# CTRL_MODULE_CORE register map
Vendor: Texas Instruments
Registers are 32-bit, access per field, reset 0x0 unless marked. A register's access mark holds for its fields unless they carry their own. Offsets are as the file gives them; [hi:lo] are bit positions; {n}, {i} and the like mark numbered series; 'fields as' and 'values as' point back to an identical list.

## CTRL_MODULE_CORE (part 5 of 5)
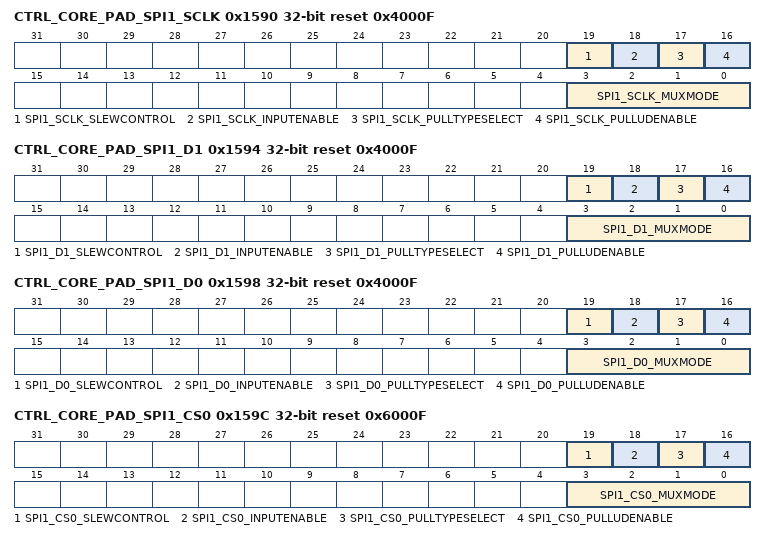
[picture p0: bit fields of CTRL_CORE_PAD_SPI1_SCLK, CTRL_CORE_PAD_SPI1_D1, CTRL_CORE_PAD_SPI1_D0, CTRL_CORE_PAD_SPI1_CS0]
0x1590 CTRL_CORE_PAD_SPI1_SCLK reset 0x4000F
  [19] SPI1_SCLK_SLEWCONTROL rw
    0=Fast_slew_is_selected; 1=Slow_slew_is_selected
  [18] SPI1_SCLK_INPUTENABLE rw
    0=Receive_mode_is_disabled; 1=Receive_mode_is_enabled
  [17] SPI1_SCLK_PULLTYPESELECT rw
    0=Pull_Down_is_selected; 1=Pull_Up_is_selected
  [16] SPI1_SCLK_PULLUDENABLE rw
    0=Enables_weak_Pull_Up/Down; 1=Disables_weak_Pull_Up/Down
  [3:0] SPI1_SCLK_MUXMODE rw
    0=SPI1_SCLK; 1=UART3_RXD; 14=GPIO4_0; 15=DRIVER_OFF
0x1594 CTRL_CORE_PAD_SPI1_D1 reset 0x4000F
  [19] SPI1_D1_SLEWCONTROL rw
    0=Fast_slew_is_selected; 1=Slow_slew_is_selected
  [18] SPI1_D1_INPUTENABLE rw
    0=Receive_mode_is_disabled; 1=Receive_mode_is_enabled
  [17] SPI1_D1_PULLTYPESELECT rw
    0=Pull_Down_is_selected; 1=Pull_Up_is_selected
  [16] SPI1_D1_PULLUDENABLE rw
    0=Enables_weak_Pull_Up/Down; 1=Disables_weak_Pull_Up/Down
  [3:0] SPI1_D1_MUXMODE rw
    0=SPI1_D1; 1=UART3_CTSN; 14=GPIO4_1; 15=DRIVER_OFF
0x1598 CTRL_CORE_PAD_SPI1_D0 reset 0x4000F
  [19] SPI1_D0_SLEWCONTROL rw
    0=Fast_slew_is_selected; 1=Slow_slew_is_selected
  [18] SPI1_D0_INPUTENABLE rw
    0=Receive_mode_is_disabled; 1=Receive_mode_is_enabled
  [17] SPI1_D0_PULLTYPESELECT rw
    0=Pull_Down_is_selected; 1=Pull_Up_is_selected
  [16] SPI1_D0_PULLUDENABLE rw
    0=Enables_weak_Pull_Up/Down; 1=Disables_weak_Pull_Up/Down
  [3:0] SPI1_D0_MUXMODE rw
    0=SPI1_D0; 1=UART3_RTSN; 14=GPIO4_2; 15=DRIVER_OFF
0x159C CTRL_CORE_PAD_SPI1_CS0 reset 0x6000F
  [19] SPI1_CS0_SLEWCONTROL rw
    0=Fast_slew_is_selected; 1=Slow_slew_is_selected
  [18] SPI1_CS0_INPUTENABLE rw
    0=Receive_mode_is_disabled; 1=Receive_mode_is_enabled
  [17] SPI1_CS0_PULLTYPESELECT rw
    0=Pull_Down_is_selected; 1=Pull_Up_is_selected
  [16] SPI1_CS0_PULLUDENABLE rw
    0=Enables_weak_Pull_Up/Down; 1=Disables_weak_Pull_Up/Down
  [3:0] SPI1_CS0_MUXMODE rw
    0=SPI1_CS0; 1=UART3_TXD; 14=GPIO4_3; 15=DRIVER_OFF
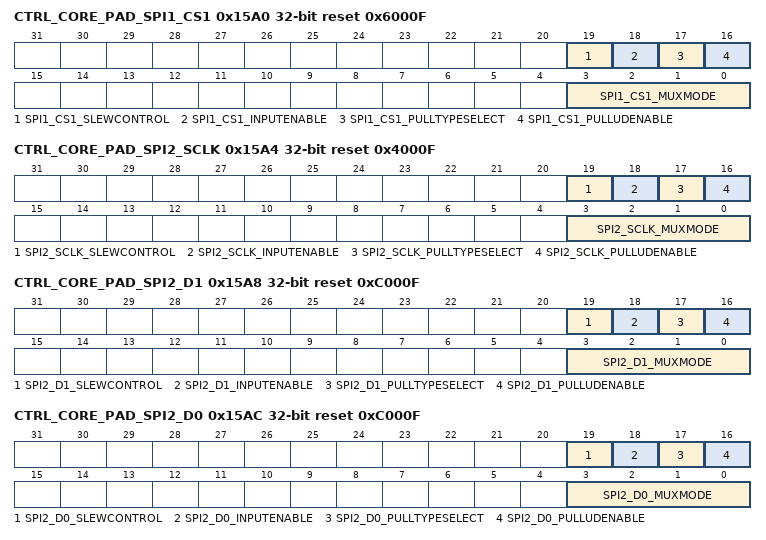
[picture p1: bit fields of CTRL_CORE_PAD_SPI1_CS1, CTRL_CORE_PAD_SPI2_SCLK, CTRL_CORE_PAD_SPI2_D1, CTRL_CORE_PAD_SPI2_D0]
0x15A0 CTRL_CORE_PAD_SPI1_CS1 reset 0x6000F
  [19] SPI1_CS1_SLEWCONTROL rw
    0=Fast_slew_is_selected; 1=Slow_slew_is_selected
  [18] SPI1_CS1_INPUTENABLE rw
    0=Receive_mode_is_disabled; 1=Receive_mode_is_enabled
  [17] SPI1_CS1_PULLTYPESELECT rw
    0=Pull_Down_is_selected; 1=Pull_Up_is_selected
  [16] SPI1_CS1_PULLUDENABLE rw
    0=Enables_weak_Pull_Up/Down; 1=Disables_weak_Pull_Up/Down
  [3:0] SPI1_CS1_MUXMODE rw
    0=SPI1_CS1; 1=SPI3_CS1; 4=TIMER6; 7=EHRPWM1_TRIPZONE_INPUT; 14=GPIO4_4; 15=DRIVER_OFF
0x15A4 CTRL_CORE_PAD_SPI2_SCLK reset 0x4000F
  [19] SPI2_SCLK_SLEWCONTROL rw
    0=Fast_slew_is_selected; 1=Slow_slew_is_selected
  [18] SPI2_SCLK_INPUTENABLE rw
    0=Receive_mode_is_disabled; 1=Receive_mode_is_enabled
  [17] SPI2_SCLK_PULLTYPESELECT rw
    0=Pull_Down_is_selected; 1=Pull_Up_is_selected
  [16] SPI2_SCLK_PULLUDENABLE rw
    0=Enables_weak_Pull_Up/Down; 1=Disables_weak_Pull_Up/Down
  [3:0] SPI2_SCLK_MUXMODE rw
    0=SPI2_SCLK; 1=UART3_RXD; 2=EHRPWM1A; 3=TIMER3; 14=GPIO4_5; 15=DRIVER_OFF
0x15A8 CTRL_CORE_PAD_SPI2_D1 reset 0xC000F
  [19] SPI2_D1_SLEWCONTROL rw
    0=Fast_slew_is_selected; 1=Slow_slew_is_selected
  [18] SPI2_D1_INPUTENABLE rw
    0=Receive_mode_is_disabled; 1=Receive_mode_is_enabled
  [17] SPI2_D1_PULLTYPESELECT rw
    0=Pull_Down_is_selected; 1=Pull_Up_is_selected
  [16] SPI2_D1_PULLUDENABLE rw
    0=Enables_weak_Pull_Up/Down; 1=Disables_weak_Pull_Up/Down
  [3:0] SPI2_D1_MUXMODE rw
    0=SPI2_D1; 1=UART3_CTSN; 3=TIMER5; 7=ECAP1_IN_PWM1_OUT; 14=GPIO4_6; 15=DRIVER_OFF
0x15AC CTRL_CORE_PAD_SPI2_D0 reset 0xC000F
  [19] SPI2_D0_SLEWCONTROL rw
    0=Fast_slew_is_selected; 1=Slow_slew_is_selected
  [18] SPI2_D0_INPUTENABLE rw
    0=Receive_mode_is_disabled; 1=Receive_mode_is_enabled
  [17] SPI2_D0_PULLTYPESELECT rw
    0=Pull_Down_is_selected; 1=Pull_Up_is_selected
  [16] SPI2_D0_PULLUDENABLE rw
    0=Enables_weak_Pull_Up/Down; 1=Disables_weak_Pull_Up/Down
  [3:0] SPI2_D0_MUXMODE rw
    0=SPI2_D0; 1=UART3_RTSN; 3=TIMER1; 14=GPIO4_7; 15=SYSBOOT7
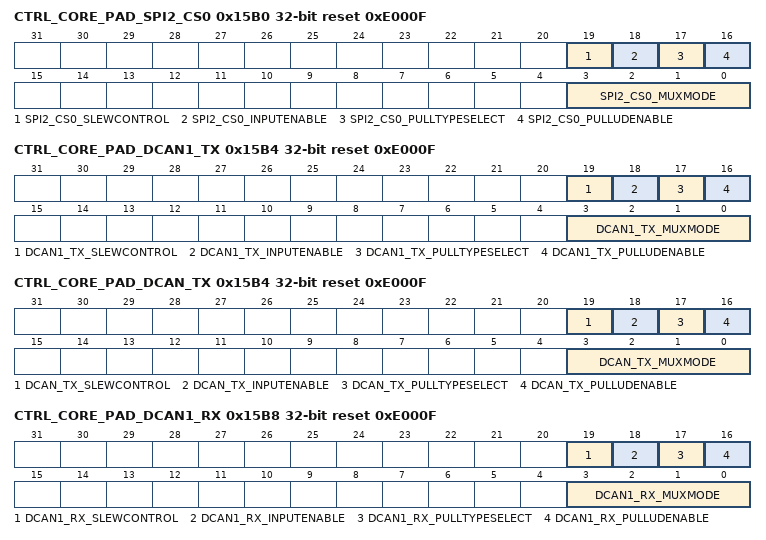
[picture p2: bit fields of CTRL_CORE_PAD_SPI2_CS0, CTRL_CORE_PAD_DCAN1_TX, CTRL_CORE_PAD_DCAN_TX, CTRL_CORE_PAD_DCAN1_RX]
0x15B0 CTRL_CORE_PAD_SPI2_CS0 reset 0xE000F
  [19] SPI2_CS0_SLEWCONTROL rw
    0=Fast_slew_is_selected; 1=Slow_slew_is_selected
  [18] SPI2_CS0_INPUTENABLE rw
    0=Receive_mode_is_disabled; 1=Receive_mode_is_enabled
  [17] SPI2_CS0_PULLTYPESELECT rw
    0=Pull_Down_is_selected; 1=Pull_Up_is_selected
  [16] SPI2_CS0_PULLUDENABLE rw
    0=Enables_weak_Pull_Up/Down; 1=Disables_weak_Pull_Up/Down
  [3:0] SPI2_CS0_MUXMODE rw
    0=SPI2_CS0; 1=UART3_TXD; 2=EHRPWM1B; 3=TIMER4; 14=GPIO4_8; 15=DRIVER_OFF
0x15B4 CTRL_CORE_PAD_DCAN1_TX reset 0xE000F — SR1.0 Only
  [19] DCAN1_TX_SLEWCONTROL rw
    0=Fast_slew_is_selected; 1=Slow_slew_is_selected
  [18] DCAN1_TX_INPUTENABLE rw
    0=Receive_mode_is_disabled; 1=Receive_mode_is_enabled
  [17] DCAN1_TX_PULLTYPESELECT rw
    0=Pull_Down_is_selected; 1=Pull_Up_is_selected
  [16] DCAN1_TX_PULLUDENABLE rw
    0=Enables_weak_Pull_Up/Down; 1=Disables_weak_Pull_Up/Down
  [3:0] DCAN1_TX_MUXMODE rw
    0=DCAN1_TX; 14=GPIO4_9; 15=DRIVER_OFF
0x15B4 CTRL_CORE_PAD_DCAN_TX reset 0xE000F — SR2.0 Only
  [19] DCAN_TX_SLEWCONTROL rw
    0=Fast_slew_is_selected; 1=Slow_slew_is_selected
  [18] DCAN_TX_INPUTENABLE rw
    0=Receive_mode_is_disabled; 1=Receive_mode_is_enabled
  [17] DCAN_TX_PULLTYPESELECT rw
    0=Pull_Down_is_selected; 1=Pull_Up_is_selected
  [16] DCAN_TX_PULLUDENABLE rw
    0=Enables_weak_Pull_Up/Down; 1=Disables_weak_Pull_Up/Down
  [3:0] DCAN_TX_MUXMODE rw
    0=DCAN_TX; 14=GPIO4_9; 15=DRIVER_OFF
0x15B8 CTRL_CORE_PAD_DCAN1_RX reset 0xE000F — SR1.0 Only
  [19] DCAN1_RX_SLEWCONTROL rw
    0=Fast_slew_is_selected; 1=Slow_slew_is_selected
  [18] DCAN1_RX_INPUTENABLE rw
    0=Receive_mode_is_disabled; 1=Receive_mode_is_enabled
  [17] DCAN1_RX_PULLTYPESELECT rw
    0=Pull_Down_is_selected; 1=Pull_Up_is_selected
  [16] DCAN1_RX_PULLUDENABLE rw
    0=Enables_weak_Pull_Up/Down; 1=Disables_weak_Pull_Up/Down
  [3:0] DCAN1_RX_MUXMODE rw
    0=DCAN1_RX; 14=GPIO4_10; 15=DRIVER_OFF
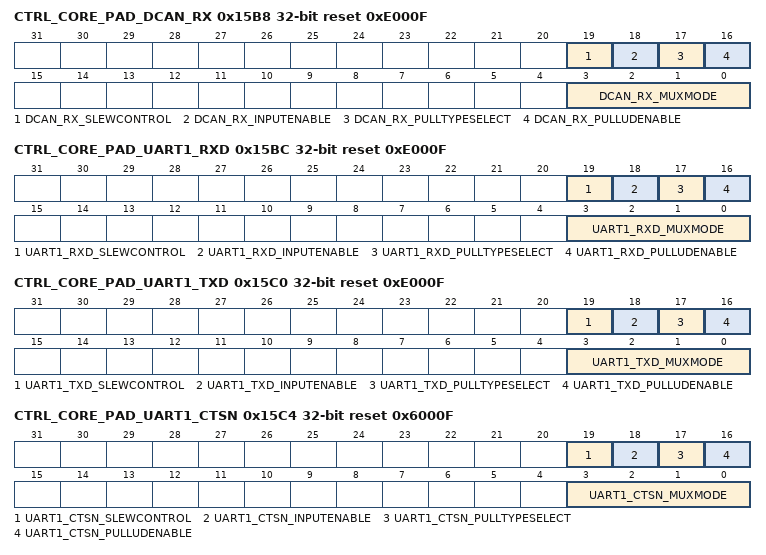
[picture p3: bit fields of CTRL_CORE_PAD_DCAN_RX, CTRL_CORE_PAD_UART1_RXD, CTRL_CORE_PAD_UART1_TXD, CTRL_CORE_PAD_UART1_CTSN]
0x15B8 CTRL_CORE_PAD_DCAN_RX reset 0xE000F — SR2.0 Only
  [19] DCAN_RX_SLEWCONTROL rw
    0=Fast_slew_is_selected; 1=Slow_slew_is_selected
  [18] DCAN_RX_INPUTENABLE rw
    0=Receive_mode_is_disabled; 1=Receive_mode_is_enabled
  [17] DCAN_RX_PULLTYPESELECT rw
    0=Pull_Down_is_selected; 1=Pull_Up_is_selected
  [16] DCAN_RX_PULLUDENABLE rw
    0=Enables_weak_Pull_Up/Down; 1=Disables_weak_Pull_Up/Down
  [3:0] DCAN_RX_MUXMODE rw
    0=DCAN_RX; 14=GPIO4_10; 15=DRIVER_OFF
0x15BC CTRL_CORE_PAD_UART1_RXD reset 0xE000F
  [19] UART1_RXD_SLEWCONTROL rw
    0=Fast_slew_is_selected; 1=Slow_slew_is_selected
  [18] UART1_RXD_INPUTENABLE rw
    0=Receive_mode_is_disabled; 1=Receive_mode_is_enabled
  [17] UART1_RXD_PULLTYPESELECT rw
    0=Pull_Down_is_selected; 1=Pull_Up_is_selected
  [16] UART1_RXD_PULLUDENABLE rw
    0=Enables_weak_Pull_Up/Down; 1=Disables_weak_Pull_Up/Down
  [3:0] UART1_RXD_MUXMODE rw
    0=UART1_RXD; 4=SPI4_D1; 5=QSPI1_RTCLK; 10=GPMC_A12; 12=DCAN2_TX_SR1.0___MCAN_TX_SR2.0 (dcan2_tx (SR1.0 Only) / mcan_tx (SR2.0 Only)); 14=GPIO4_13; 15=DRIVER_OFF
0x15C0 CTRL_CORE_PAD_UART1_TXD reset 0xE000F
  [19] UART1_TXD_SLEWCONTROL rw
    0=Fast_slew_is_selected; 1=Slow_slew_is_selected
  [18] UART1_TXD_INPUTENABLE rw
    0=Receive_mode_is_disabled; 1=Receive_mode_is_enabled
  [17] UART1_TXD_PULLTYPESELECT rw
    0=Pull_Down_is_selected; 1=Pull_Up_is_selected
  [16] UART1_TXD_PULLUDENABLE rw
    0=Enables_weak_Pull_Up/Down; 1=Disables_weak_Pull_Up/Down
  [3:0] UART1_TXD_MUXMODE rw
    0=UART1_TXD; 4=SPI4_D0; 10=GPMC_A13; 12=DCAN2_RX_SR1.0___MCAN_RX_SR2.0 (dcan2_rx (SR1.0 Only) / mcan_rx (SR2.0 Only)); 14=GPIO4_14; 15=DRIVER_OFF
0x15C4 CTRL_CORE_PAD_UART1_CTSN reset 0x6000F
  [19] UART1_CTSN_SLEWCONTROL rw
    0=Fast_slew_is_selected; 1=Slow_slew_is_selected
  [18] UART1_CTSN_INPUTENABLE rw
    0=Receive_mode_is_disabled; 1=Receive_mode_is_enabled
  [17] UART1_CTSN_PULLTYPESELECT rw
    0=Pull_Down_is_selected; 1=Pull_Up_is_selected
  [16] UART1_CTSN_PULLUDENABLE rw
    0=Enables_weak_Pull_Up/Down; 1=Disables_weak_Pull_Up/Down
  [3:0] UART1_CTSN_MUXMODE rw
    0=UART1_CTSN; 1=XREF_CLK1; 2=UART3_RXD; 3=GPMC_A16; 4=SPI4_SCLK; 5=SPI1_CS2; 6=TIMER3; 7=EHRPWM1_SYNCI; 8=CLKOUT0; 9=VIN2A_HSYNC0; 10=GPMC_A12; 11=GPMC_CLK; 12=DCAN1_TX_SR1.0___DCAN_TX_SR2.0 (dcan1_tx (SR1.0 Only) / dcan_tx (SR2.0 Only)); 14=GPIO4_15; 15=DRIVER_OFF
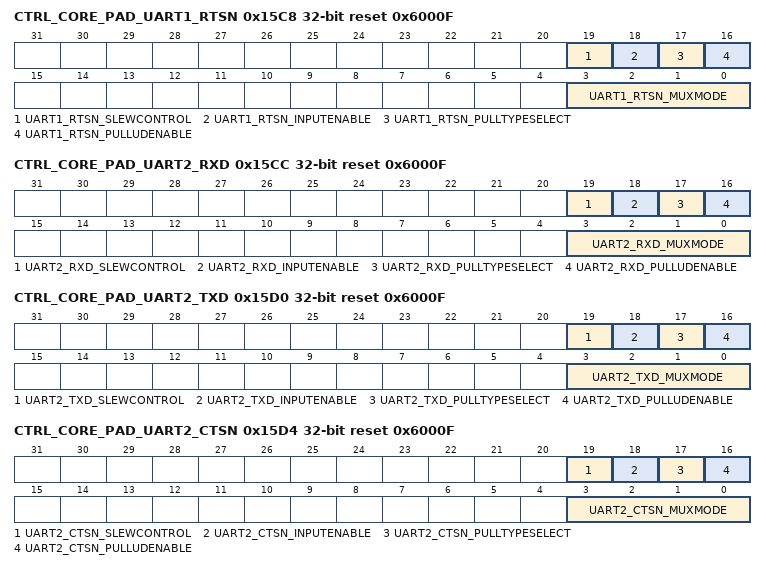
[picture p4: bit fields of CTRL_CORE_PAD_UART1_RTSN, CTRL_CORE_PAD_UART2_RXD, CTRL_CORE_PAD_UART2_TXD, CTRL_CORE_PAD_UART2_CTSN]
0x15C8 CTRL_CORE_PAD_UART1_RTSN reset 0x6000F
  [19] UART1_RTSN_SLEWCONTROL rw
    0=Fast_slew_is_selected; 1=Slow_slew_is_selected
  [18] UART1_RTSN_INPUTENABLE rw
    0=Receive_mode_is_disabled; 1=Receive_mode_is_enabled
  [17] UART1_RTSN_PULLTYPESELECT rw
    0=Pull_Down_is_selected; 1=Pull_Up_is_selected
  [16] UART1_RTSN_PULLUDENABLE rw
    0=Enables_weak_Pull_Up/Down; 1=Disables_weak_Pull_Up/Down
  [3:0] UART1_RTSN_MUXMODE rw
    0=UART1_RTSN; 2=UART3_TXD; 3=GPMC_A17; 4=SPI4_CS0; 5=SPI1_CS3; 6=TIMER4; 7=EHRPWM1_SYNCO; 8=QSPI1_RTCLK; 9=VIN2A_VSYNC0; 10=GPMC_A13; 12=DCAN1_RX_SR1.0___DCAN_RX_SR2.0 (dcan1_rx (SR1.0 Only) / dcan_rx (SR2.0 Only)); 14=GPIO4_16; 15=DRIVER_OFF
0x15CC CTRL_CORE_PAD_UART2_RXD reset 0x6000F
  [19] UART2_RXD_SLEWCONTROL rw
    0=Fast_slew_is_selected; 1=Slow_slew_is_selected
  [18] UART2_RXD_INPUTENABLE rw
    0=Receive_mode_is_disabled; 1=Receive_mode_is_enabled
  [17] UART2_RXD_PULLTYPESELECT rw
    0=Pull_Down_is_selected; 1=Pull_Up_is_selected
  [16] UART2_RXD_PULLUDENABLE rw
    0=Enables_weak_Pull_Up/Down; 1=Disables_weak_Pull_Up/Down
  [3:0] UART2_RXD_MUXMODE rw
    0=UART2_RXD; 4=SPI3_D1; 6=TIMER1; 7=EHRPWM1A; 10=GPMC_CLK; 11=GPMC_A12; 12=DCAN1_TX_SR1.0___DCAN_TX_SR2.0 (dcan1_tx (SR1.0 Only) / dcan_tx (SR2.0 Only)); 14=GPIO4_17; 15=DRIVER_OFF
0x15D0 CTRL_CORE_PAD_UART2_TXD reset 0x6000F
  [19] UART2_TXD_SLEWCONTROL rw
    0=Fast_slew_is_selected; 1=Slow_slew_is_selected
  [18] UART2_TXD_INPUTENABLE rw
    0=Receive_mode_is_disabled; 1=Receive_mode_is_enabled
  [17] UART2_TXD_PULLTYPESELECT rw
    0=Pull_Down_is_selected; 1=Pull_Up_is_selected
  [16] UART2_TXD_PULLUDENABLE rw
    0=Enables_weak_Pull_Up/Down; 1=Disables_weak_Pull_Up/Down
  [3:0] UART2_TXD_MUXMODE rw
    0=UART2_TXD; 4=SPI3_D0; 6=TIMER2; 7=EHRPWM1B; 11=GPMC_A13; 12=DCAN1_RX_SR1.0___DCAN_RX_SR2.0 (dcan1_rx (SR1.0 Only) / dcan_rx (SR2.0 Only)); 14=GPIO4_18; 15=DRIVER_OFF
0x15D4 CTRL_CORE_PAD_UART2_CTSN reset 0x6000F
  [19] UART2_CTSN_SLEWCONTROL rw
    0=Fast_slew_is_selected; 1=Slow_slew_is_selected
  [18] UART2_CTSN_INPUTENABLE rw
    0=Receive_mode_is_disabled; 1=Receive_mode_is_enabled
  [17] UART2_CTSN_PULLTYPESELECT rw
    0=Pull_Down_is_selected; 1=Pull_Up_is_selected
  [16] UART2_CTSN_PULLUDENABLE rw
    0=Enables_weak_Pull_Up/Down; 1=Disables_weak_Pull_Up/Down
  [3:0] UART2_CTSN_MUXMODE rw
    0=UART2_CTSN; 2=XREF_CLK1; 3=GPMC_A18; 4=SPI3_SCLK; 5=QSPI1_CS1; 6=TIMER7; 9=VIN2A_HSYNC0; 10=GPMC_CLK; 12=DCAN2_TX_SR1.0___MCAN_TX_SR2.0 (dcan2_tx (SR1.0 Only) / mcan_tx (SR2.0 Only)); 14=GPIO4_19; 15=DRIVER_OFF
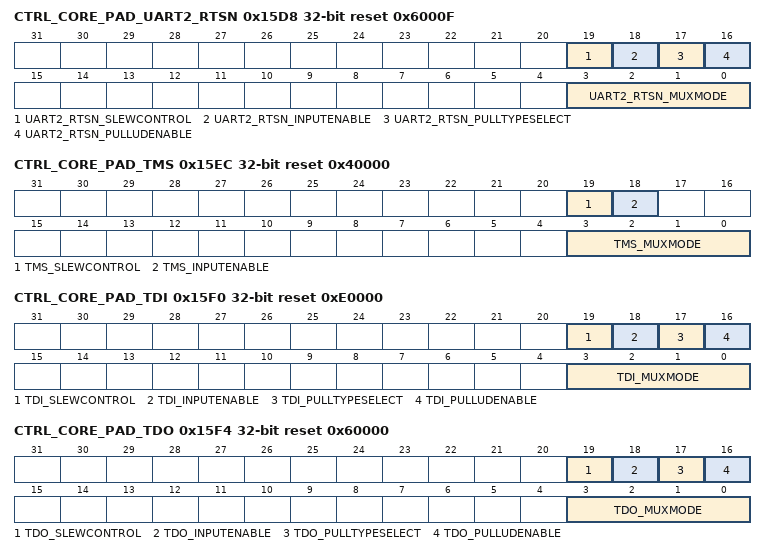
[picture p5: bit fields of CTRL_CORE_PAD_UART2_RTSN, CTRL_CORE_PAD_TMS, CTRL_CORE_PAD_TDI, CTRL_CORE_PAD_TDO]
0x15D8 CTRL_CORE_PAD_UART2_RTSN reset 0x6000F
  [19] UART2_RTSN_SLEWCONTROL rw
    0=Fast_slew_is_selected; 1=Slow_slew_is_selected
  [18] UART2_RTSN_INPUTENABLE rw
    0=Receive_mode_is_disabled; 1=Receive_mode_is_enabled
  [17] UART2_RTSN_PULLTYPESELECT rw
    0=Pull_Down_is_selected; 1=Pull_Up_is_selected
  [16] UART2_RTSN_PULLUDENABLE rw
    0=Enables_weak_Pull_Up/Down; 1=Disables_weak_Pull_Up/Down
  [3:0] UART2_RTSN_MUXMODE rw
    0=UART2_RTSN; 1=ECAP1_IN_PWM1_OUT; 3=GPMC_A19; 4=SPI3_CS0; 6=TIMER8; 9=VIN2A_VSYNC0; 12=DCAN2_RX_SR1.0___MCAN_RX_SR2.0 (dcan2_rx (SR1.0 Only) / mcan_rx (SR2.0 Only)); 14=GPIO4_20; 15=DRIVER_OFF
0x15DC CTRL_CORE_PAD_I2C1_SDA reset 0x40000
  [18] I2C1_SDA_INPUTENABLE rw
    0=Receive_mode_is_disabled; 1=Receive_mode_is_enabled
0x15E0 CTRL_CORE_PAD_I2C1_SCL reset 0x40000
  [18] I2C1_SCL_INPUTENABLE rw
    0=Receive_mode_is_disabled; 1=Receive_mode_is_enabled
0x15E4 CTRL_CORE_PAD_I2C2_SDA reset 0x40000
  [18] I2C2_SDA_INPUTENABLE rw
    0=Receive_mode_is_disabled; 1=Receive_mode_is_enabled
0x15E8 CTRL_CORE_PAD_I2C2_SCL reset 0x40000
  [18] I2C2_SCL_INPUTENABLE rw
    0=Receive_mode_is_disabled; 1=Receive_mode_is_enabled
0x15EC CTRL_CORE_PAD_TMS reset 0x40000
  [19] TMS_SLEWCONTROL rw
    0=Fast_slew_is_selected; 1=Slow_slew_is_selected
  [18] TMS_INPUTENABLE rw
    0=Receive_mode_is_disabled; 1=Receive_mode_is_enabled
  [3:0] TMS_MUXMODE rw
    0=TMS
0x15F0 CTRL_CORE_PAD_TDI reset 0xE0000
  [19] TDI_SLEWCONTROL rw
    0=Fast_slew_is_selected; 1=Slow_slew_is_selected
  [18] TDI_INPUTENABLE rw
    0=Receive_mode_is_disabled; 1=Receive_mode_is_enabled
  [17] TDI_PULLTYPESELECT rw
    0=Pull_Down_is_selected; 1=Pull_Up_is_selected
  [16] TDI_PULLUDENABLE rw
    0=Enables_weak_Pull_Up/Down; 1=Disables_weak_Pull_Up/Down
  [3:0] TDI_MUXMODE rw
    0=TDI; 14=GPIO4_25; 15=DRIVER_OFF
0x15F4 CTRL_CORE_PAD_TDO reset 0x60000
  [19] TDO_SLEWCONTROL rw
    0=Fast_slew_is_selected; 1=Slow_slew_is_selected
  [18] TDO_INPUTENABLE rw
    0=Receive_mode_is_disabled; 1=Receive_mode_is_enabled
  [17] TDO_PULLTYPESELECT rw
    0=Pull_Down_is_selected; 1=Pull_Up_is_selected
  [16] TDO_PULLUDENABLE rw
    0=Enables_weak_Pull_Up/Down; 1=Disables_weak_Pull_Up/Down
  [3:0] TDO_MUXMODE rw
    0=TDO; 14=GPIO4_26; 15=DRIVER_OFF
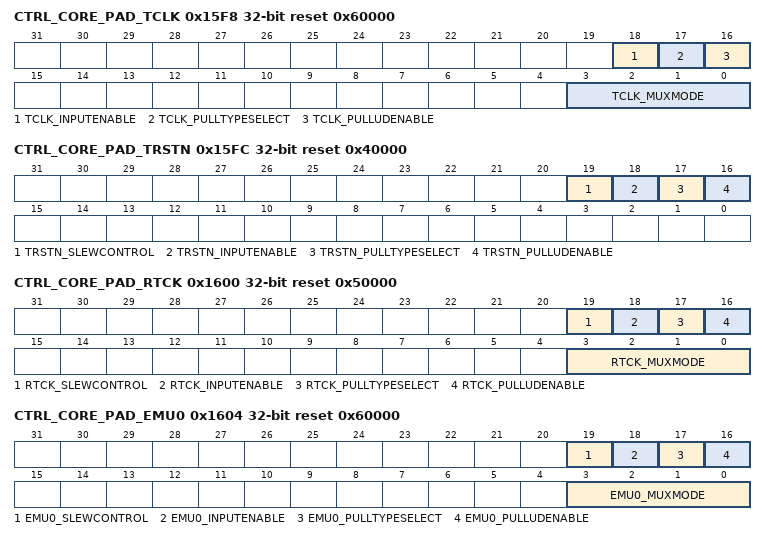
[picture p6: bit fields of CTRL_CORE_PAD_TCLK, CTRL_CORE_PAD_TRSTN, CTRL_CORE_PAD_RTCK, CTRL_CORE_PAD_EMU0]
0x15F8 CTRL_CORE_PAD_TCLK reset 0x60000
  [18] TCLK_INPUTENABLE rw
    0=Receive_mode_is_disabled; 1=Receive_mode_is_enabled
  [17] TCLK_PULLTYPESELECT rw
    0=Pull_Down_is_selected; 1=Pull_Up_is_selected
  [16] TCLK_PULLUDENABLE rw
    0=Enables_weak_Pull_Up/Down; 1=Disables_weak_Pull_Up/Down
  [3:0] TCLK_MUXMODE rw
    0=TCLK
0x15FC CTRL_CORE_PAD_TRSTN reset 0x40000
  [19] TRSTN_SLEWCONTROL rw
    0=Fast_slew_is_selected; 1=Slow_slew_is_selected
  [18] TRSTN_INPUTENABLE rw
    0=Receive_mode_is_disabled; 1=Receive_mode_is_enabled
  [17] TRSTN_PULLTYPESELECT rw
    0=Pull_Down_is_selected; 1=Pull_Up_is_selected
  [16] TRSTN_PULLUDENABLE rw
    0=Enables_weak_Pull_Up/Down; 1=Disables_weak_Pull_Up/Down
0x1600 CTRL_CORE_PAD_RTCK reset 0x50000
  [19] RTCK_SLEWCONTROL rw
    0=Fast_slew_is_selected; 1=Slow_slew_is_selected
  [18] RTCK_INPUTENABLE rw
    0=Receive_mode_is_disabled; 1=Receive_mode_is_enabled
  [17] RTCK_PULLTYPESELECT rw
    0=Pull_Down_is_selected; 1=Pull_Up_is_selected
  [16] RTCK_PULLUDENABLE rw
    0=Enables_weak_Pull_Up/Down; 1=Disables_weak_Pull_Up/Down
  [3:0] RTCK_MUXMODE rw
    0=RTCK; 14=GPIO4_27; 15=DRIVER_OFF
0x1604 CTRL_CORE_PAD_EMU0 reset 0x60000
  [19] EMU0_SLEWCONTROL rw
    0=Fast_slew_is_selected; 1=Slow_slew_is_selected
  [18] EMU0_INPUTENABLE rw
    0=Receive_mode_is_disabled; 1=Receive_mode_is_enabled
  [17] EMU0_PULLTYPESELECT rw
    0=Pull_Down_is_selected; 1=Pull_Up_is_selected
  [16] EMU0_PULLUDENABLE rw
    0=Enables_weak_Pull_Up/Down; 1=Disables_weak_Pull_Up/Down
  [3:0] EMU0_MUXMODE rw
    0=EMU0; 14=GPIO4_28; 15=DRIVER_OFF
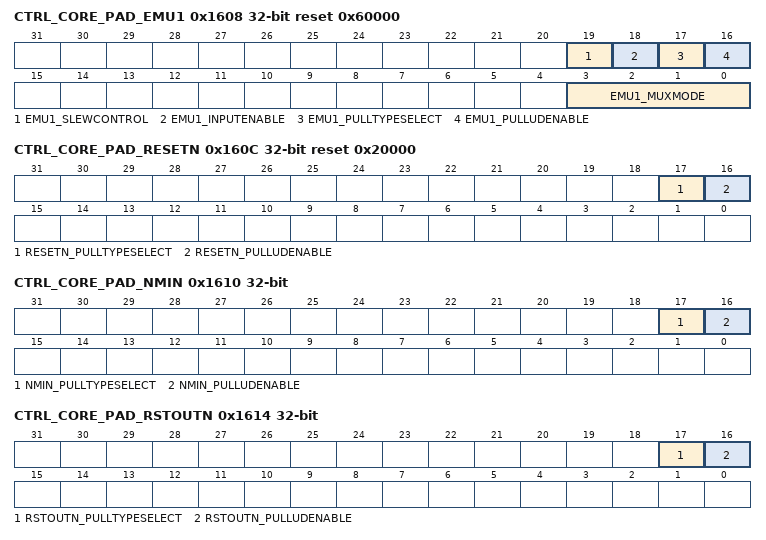
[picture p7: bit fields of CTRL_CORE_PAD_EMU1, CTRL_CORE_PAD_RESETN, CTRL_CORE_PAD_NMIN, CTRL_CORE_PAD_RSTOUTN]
0x1608 CTRL_CORE_PAD_EMU1 reset 0x60000
  [19] EMU1_SLEWCONTROL rw
    0=Fast_slew_is_selected; 1=Slow_slew_is_selected
  [18] EMU1_INPUTENABLE rw
    0=Receive_mode_is_disabled; 1=Receive_mode_is_enabled
  [17] EMU1_PULLTYPESELECT rw
    0=Pull_Down_is_selected; 1=Pull_Up_is_selected
  [16] EMU1_PULLUDENABLE rw
    0=Enables_weak_Pull_Up/Down; 1=Disables_weak_Pull_Up/Down
  [3:0] EMU1_MUXMODE rw
    0=EMU1; 14=GPIO4_29; 15=DRIVER_OFF
0x160C CTRL_CORE_PAD_RESETN reset 0x20000
  [17] RESETN_PULLTYPESELECT rw
    0=Pull_Down_is_selected; 1=Pull_Up_is_selected
  [16] RESETN_PULLUDENABLE rw
    0=Enables_weak_Pull_Up/Down; 1=Disables_weak_Pull_Up/Down
0x1610 CTRL_CORE_PAD_NMIN
  [17] NMIN_PULLTYPESELECT rw
    0=Pull_Down_is_selected; 1=Pull_Up_is_selected
  [16] NMIN_PULLUDENABLE rw
    0=Enables_weak_Pull_Up/Down; 1=Disables_weak_Pull_Up/Down
0x1614 CTRL_CORE_PAD_RSTOUTN
  [17] RSTOUTN_PULLTYPESELECT rw
    0=Pull_Down_is_selected; 1=Pull_Up_is_selected
  [16] RSTOUTN_PULLUDENABLE rw
    0=Enables_weak_Pull_Up/Down; 1=Disables_weak_Pull_Up/Down
0x1A10 CTRL_CORE_L4_CFG_ROLES_0_LOWER rw — L4 Config Protection Group 0 Roles [31:0]
  [31:0] L4_CFG_ROLES_0_0
0x1A14 CTRL_CORE_L4_CFG_ROLES_0_UPPER rw — L4 Config Protection Group 0 Roles [63:32]
  [31:0] L4_CFG_ROLES_0_1
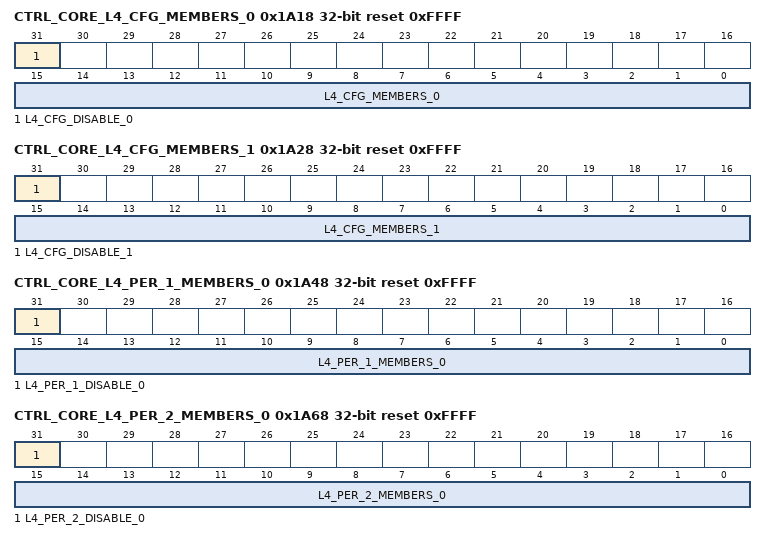
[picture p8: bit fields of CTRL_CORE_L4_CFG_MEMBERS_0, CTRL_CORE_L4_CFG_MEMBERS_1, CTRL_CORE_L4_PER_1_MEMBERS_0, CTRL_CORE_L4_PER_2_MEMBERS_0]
0x1A18 CTRL_CORE_L4_CFG_MEMBERS_0 reset 0xFFFF — L4 Config Protection Group 0 Members and lock
  [31] L4_CFG_DISABLE_0 rw — L4 Config Protection Group 0 Lock
  [15:0] L4_CFG_MEMBERS_0 rw — L4 Config Protection Group 0 Members [15:0]
0x1A20 CTRL_CORE_L4_CFG_ROLES_1_LOWER rw — L4 Config Protection Group 1 Roles [31:0]
  [31:0] L4_CFG_ROLES_1_0
0x1A24 CTRL_CORE_L4_CFG_ROLES_1_UPPER rw — L4 Config Protection Group 1 Roles [63:32]
  [31:0] L4_CFG_ROLES_1_1
0x1A28 CTRL_CORE_L4_CFG_MEMBERS_1 reset 0xFFFF — L4 Config Protection Group 1 Members and lock
  [31] L4_CFG_DISABLE_1 rw — L4 Config Protection Group 1 Lock
  [15:0] L4_CFG_MEMBERS_1 rw — L4 Config Protection Group 1 Members [15:0]
0x1A40 CTRL_CORE_L4_PER_1_ROLES_0_LOWER rw — L4 Per 1 Protection Group 0 Roles [31:0]
  [31:0] L4_PER_1_ROLES_0_0
0x1A44 CTRL_CORE_L4_PER_1_ROLES_0_UPPER rw — L4 Per 1 Protection Group 0 Roles [63:32]
  [31:0] L4_PER_1_ROLES_0_1
0x1A48 CTRL_CORE_L4_PER_1_MEMBERS_0 reset 0xFFFF — L4 Per 1 Protection Group 0 Members and lock
  [31] L4_PER_1_DISABLE_0 rw — L4 Per 1 Protection Group 0 Lock
  [15:0] L4_PER_1_MEMBERS_0 rw — L4 Per 1 Protection Group 0 Members [15:0]
0x1A60 CTRL_CORE_L4_PER_2_ROLES_0_LOWER rw — L4 Per 2 Protection Group 0 Roles [31:0]
  [31:0] L4_PER_2_ROLES_0_0
0x1A64 CTRL_CORE_L4_PER_2_ROLES_0_UPPER rw — L4 Per 2 Protection Group 0 Roles [63:32]
  [31:0] L4_PER_2_ROLES_0_1
0x1A68 CTRL_CORE_L4_PER_2_MEMBERS_0 reset 0xFFFF — L4 Per 2 Protection Group 0 Members and lock
  [31] L4_PER_2_DISABLE_0 rw — L4 Per 2 Protection Group 0 Lock
  [15:0] L4_PER_2_MEMBERS_0 rw — L4 Per 2 Protection Group 0 Members [15:0]
0x1A70 CTRL_CORE_L4_PER_3_ROLES_0_LOWER rw — L4 Per 3 Protection Group 0 Roles [31:0]
  [31:0] L4_PER_3_ROLES_0_0
0x1A74 CTRL_CORE_L4_PER_3_ROLES_0_UPPER rw — L4 Per 3 Protection Group 0 Roles [63:32]
  [31:0] L4_PER_3_ROLES_0_1
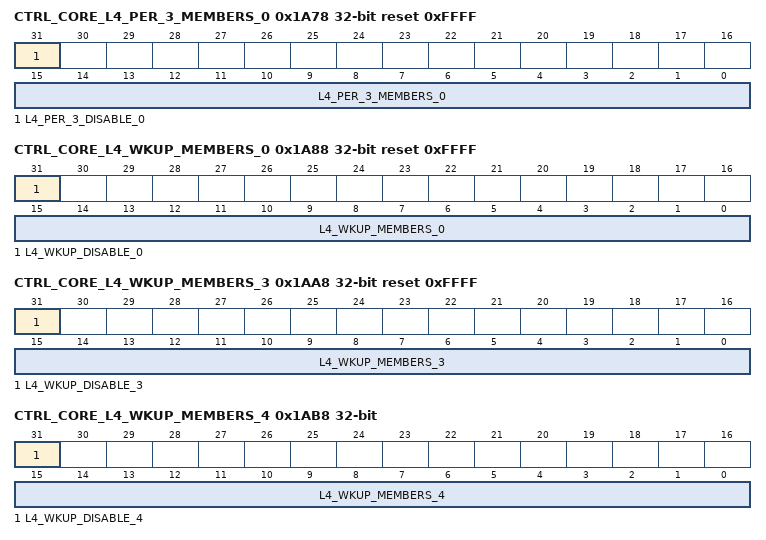
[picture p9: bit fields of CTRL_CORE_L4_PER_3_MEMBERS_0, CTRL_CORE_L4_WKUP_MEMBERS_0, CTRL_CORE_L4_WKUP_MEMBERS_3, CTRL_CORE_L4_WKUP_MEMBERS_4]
0x1A78 CTRL_CORE_L4_PER_3_MEMBERS_0 reset 0xFFFF — L4 Per 3 Protection Group 0 Members and lock
  [31] L4_PER_3_DISABLE_0 rw — L4 Per 3 Protection Group 0 Lock
  [15:0] L4_PER_3_MEMBERS_0 rw — L4 Per 3 Protection Group 0 Members [15:0]
0x1A80 CTRL_CORE_L4_WKUP_ROLES_0_LOWER rw — L4 Wakeup Protection Group 0 Roles [31:0]
  [31:0] L4_WKUP_ROLES_0_0
0x1A84 CTRL_CORE_L4_WKUP_ROLES_0_UPPER rw — L4 Wakeup Protection Group 0 Roles [63:32]
  [31:0] L4_WKUP_ROLES_0_1
0x1A88 CTRL_CORE_L4_WKUP_MEMBERS_0 reset 0xFFFF — L4 Wakeup Protection Group 0 Members and lock
  [31] L4_WKUP_DISABLE_0 rw — L4 Wakeup Protection Group 0 Lock
  [15:0] L4_WKUP_MEMBERS_0 rw — L4 Wakeup Protection Group 0 Members [15:0]
0x1AA0 CTRL_CORE_L4_WKUP_ROLES_3_LOWER rw — L4 Wakeup Protection Group 3 Roles [31:0]
  [31:0] L4_WKUP_ROLES_3_0
0x1AA4 CTRL_CORE_L4_WKUP_ROLES_3_UPPER rw — L4 Wakeup Protection Group 3 Roles [63:32]
  [31:0] L4_WKUP_ROLES_3_1
0x1AA8 CTRL_CORE_L4_WKUP_MEMBERS_3 reset 0xFFFF — L4 Wakeup Protection Group 3 Members and lock
  [31] L4_WKUP_DISABLE_3 rw — L4 Wakeup Protection Group 3 Lock
  [15:0] L4_WKUP_MEMBERS_3 rw — L4 Wakeup Protection Group 3 Members [15:0]
0x1AB0 CTRL_CORE_L4_WKUP_ROLES_4_LOWER rw reset 0xC0 — L4 Wakeup Protection Group 4 Roles [31:0]
  [31:0] L4_WKUP_ROLES_4_0
0x1AB4 CTRL_CORE_L4_WKUP_ROLES_4_UPPER rw — L4 Wakeup Protection Group 4 Roles [63:32]
  [31:0] L4_WKUP_ROLES_4_1
0x1AB8 CTRL_CORE_L4_WKUP_MEMBERS_4 — L4 Wakeup Protection Group 4 Members and lock
  [31] L4_WKUP_DISABLE_4 rw — L4 Wakeup Protection Group 4 Lock
  [15:0] L4_WKUP_MEMBERS_4 rw — L4 Wakeup Protection Group 4 Members [15:0]
{0x1B38+4i} CTRL_CORE_STD_FUSE_OPP_VDD_DSPEVE_LVT_{i} ro (i=0..4) — Standard Fuse OPP VDD_GPU [{32i+31}:{32i}]. Register shows part of the chip eFuse configuration on the OCP interface. Reading at the address of one of these registers provides a direct view into a part of the eFuse chain.
  [31:0] STD_FUSE_OPP_VDD_DSPEVE_LVT_{i}
{0x1B60+4i} CTRL_CORE_STD_FUSE_OPP_VDD_CORE_LVT_{i} ro (i=0..4) — Standard Fuse OPP VDD_CORE [{32i+31}:{32i}]. Register shows part of the chip eFuse configuration on the OCP interface. Reading at the address of one of these registers provides a direct view into a part of the eFuse chain.
  [31:0] STD_FUSE_OPP_VDD_CORE_LVT_{i}
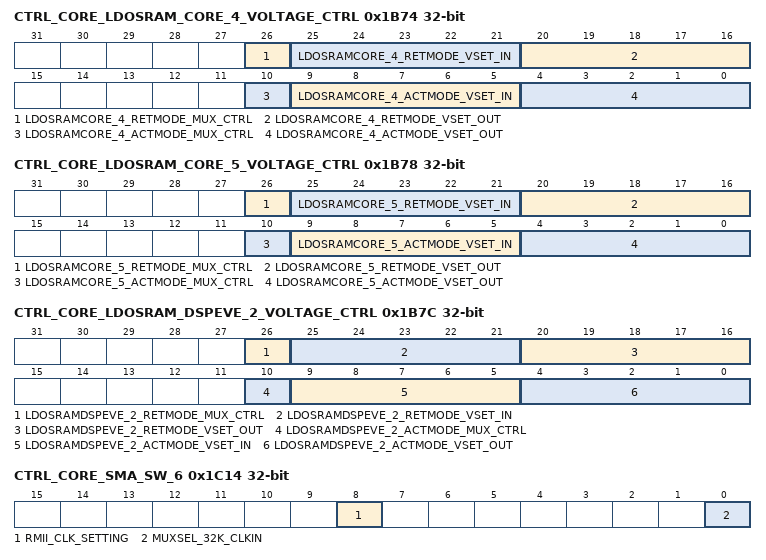
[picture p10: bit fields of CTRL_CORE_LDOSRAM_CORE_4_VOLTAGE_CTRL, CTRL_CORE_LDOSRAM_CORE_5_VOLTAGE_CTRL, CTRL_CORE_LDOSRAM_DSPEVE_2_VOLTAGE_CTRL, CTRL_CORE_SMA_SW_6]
0x1B74 CTRL_CORE_LDOSRAM_CORE_4_VOLTAGE_CTRL — CORE 4th SRAM LDO Control register
  [26] LDOSRAMCORE_4_RETMODE_MUX_CTRL rw — Override control of EFUSE Retention Mode Voltage value
    0=EFUSE (eFuse value is used); 1=OCP (Override value is used)
  [25:21] LDOSRAMCORE_4_RETMODE_VSET_IN ro — EFUSE Retention Mode Voltage value (vset[9:5])
  [20:16] LDOSRAMCORE_4_RETMODE_VSET_OUT rw — Override value for Retention Mode Voltage
  [10] LDOSRAMCORE_4_ACTMODE_MUX_CTRL rw — Override control of EFUSE Active Mode Voltage value
    values as LDOSRAMCORE_4_RETMODE_MUX_CTRL
  [9:5] LDOSRAMCORE_4_ACTMODE_VSET_IN ro — EFUSE Active Mode Voltage value (vset[4:0])
  [4:0] LDOSRAMCORE_4_ACTMODE_VSET_OUT rw — Override value for Active Mode Voltage value
0x1B78 CTRL_CORE_LDOSRAM_CORE_5_VOLTAGE_CTRL — CORE 5th SRAM LDO Control register
  [26] LDOSRAMCORE_5_RETMODE_MUX_CTRL rw — Override control of EFUSE Retention Mode Voltage value
    values as CTRL_CORE_LDOSRAM_CORE_4_VOLTAGE_CTRL.LDOSRAMCORE_4_RETMODE_MUX_CTRL
  [25:21] LDOSRAMCORE_5_RETMODE_VSET_IN ro — EFUSE Retention Mode Voltage value (vset[9:5])
  [20:16] LDOSRAMCORE_5_RETMODE_VSET_OUT rw — Override value for Retention Mode Voltage
  [10] LDOSRAMCORE_5_ACTMODE_MUX_CTRL rw — Override control of EFUSE Active Mode Voltage value
    values as CTRL_CORE_LDOSRAM_CORE_4_VOLTAGE_CTRL.LDOSRAMCORE_4_RETMODE_MUX_CTRL
  [9:5] LDOSRAMCORE_5_ACTMODE_VSET_IN ro — EFUSE Active Mode Voltage value (vset[4:0])
  [4:0] LDOSRAMCORE_5_ACTMODE_VSET_OUT rw — Override value for Active Mode Voltage value
0x1B7C CTRL_CORE_LDOSRAM_DSPEVE_2_VOLTAGE_CTRL — DSPEVE 2nd SRAM LDO Control register
  [26] LDOSRAMDSPEVE_2_RETMODE_MUX_CTRL rw — Override control of EFUSE Retention Mode Voltage value
    values as CTRL_CORE_LDOSRAM_CORE_4_VOLTAGE_CTRL.LDOSRAMCORE_4_RETMODE_MUX_CTRL
  [25:21] LDOSRAMDSPEVE_2_RETMODE_VSET_IN ro — EFUSE Retention Mode Voltage value (vset[9:5])
  [20:16] LDOSRAMDSPEVE_2_RETMODE_VSET_OUT rw — Override value for Retention Mode Voltage
  [10] LDOSRAMDSPEVE_2_ACTMODE_MUX_CTRL rw — Override control of EFUSE Active Mode Voltage value
    values as CTRL_CORE_LDOSRAM_CORE_4_VOLTAGE_CTRL.LDOSRAMCORE_4_RETMODE_MUX_CTRL
  [9:5] LDOSRAMDSPEVE_2_ACTMODE_VSET_IN ro — EFUSE Active Mode Voltage value (vset[4:0])
  [4:0] LDOSRAMDSPEVE_2_ACTMODE_VSET_OUT rw — Override value for Active Mode Voltage value
0x1C04 CTRL_CORE_SMA_SW_2 rw — OCP Spare Register
  [31:0] SMA_SW_2 — OCP spare register
0x1C08 CTRL_CORE_SMA_SW_3 rw — OCP Spare Register
  [31:0] SMA_SW_3 — OCP spare register
0x1C14 CTRL_CORE_SMA_SW_6 — OCP Spare Register
  [8] RMII_CLK_SETTING rw — RMII CLK setting 0x0: Internal clock from DPLL_GMAC 0x1: Reserved
  [0] MUXSEL_32K_CLKIN rw — Setting for mux to select 32KHz clock input to PRCM. This bit must NOT be modified by software. The 32kHz clock selection is done through the device sysboot[9:8] signals.
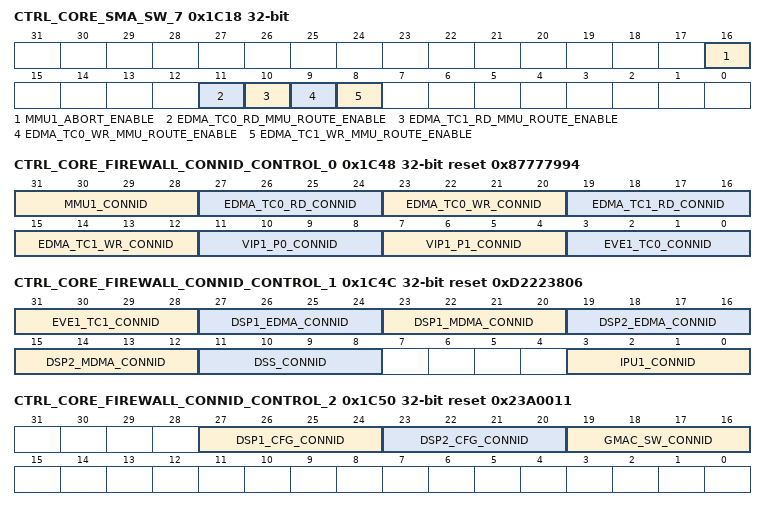
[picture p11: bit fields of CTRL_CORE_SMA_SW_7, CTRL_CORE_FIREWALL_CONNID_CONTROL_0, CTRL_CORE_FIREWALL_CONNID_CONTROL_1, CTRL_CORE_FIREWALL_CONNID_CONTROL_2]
0x1C18 CTRL_CORE_SMA_SW_7 — OCP Spare Register
  [16] MMU1_ABORT_ENABLE rw
  [11] EDMA_TC0_RD_MMU_ROUTE_ENABLE rw — EDMA TC0 RD traffic MMU route enable
  [10] EDMA_TC1_RD_MMU_ROUTE_ENABLE rw — EDMA TC1 RD traffic MMU route enable
  [9] EDMA_TC0_WR_MMU_ROUTE_ENABLE rw — EDMA TC0 WR traffic MMU route enable
  [8] EDMA_TC1_WR_MMU_ROUTE_ENABLE rw — EDMA TC1 WR traffic MMU route enable
0x1C48 CTRL_CORE_FIREWALL_CONNID_CONTROL_0 rw reset 0x87777994 — Firewall ConnID control register
  [31:28] MMU1_CONNID, [27:24] EDMA_TC0_RD_CONNID, [23:20] EDMA_TC0_WR_CONNID, [19:16] EDMA_TC1_RD_CONNID, [15:12] EDMA_TC1_WR_CONNID, [11:8] VIP1_P0_CONNID, [7:4] VIP1_P1_CONNID, [3:0] EVE1_TC0_CONNID
0x1C4C CTRL_CORE_FIREWALL_CONNID_CONTROL_1 reset 0xD2223806 — Firewall ConnID control register
  [31:28] EVE1_TC1_CONNID rw, [27:24] DSP1_EDMA_CONNID rw, [23:20] DSP1_MDMA_CONNID rw, [19:16] DSP2_EDMA_CONNID rw, [15:12] DSP2_MDMA_CONNID rw, [11:8] DSS_CONNID rw, [3:0] IPU1_CONNID rw
0x1C50 CTRL_CORE_FIREWALL_CONNID_CONTROL_2 reset 0x23A0011 — Firewall ConnID control register
  [27:24] DSP1_CFG_CONNID rw, [23:20] DSP2_CFG_CONNID rw, [19:16] GMAC_SW_CONNID rw
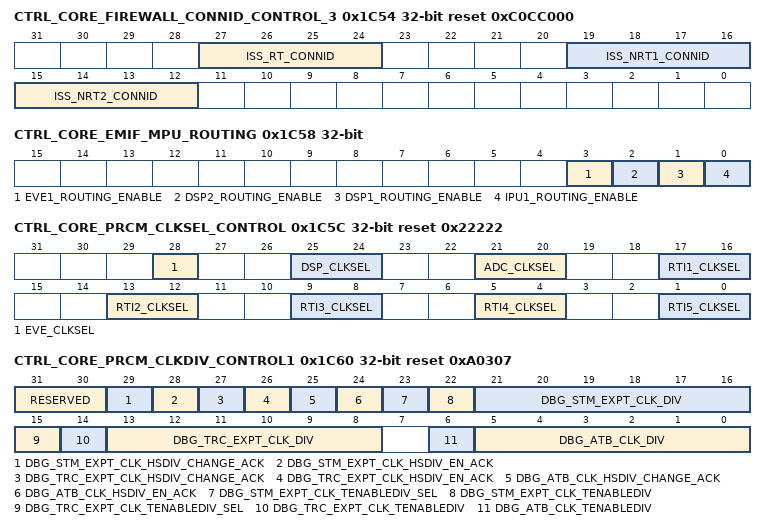
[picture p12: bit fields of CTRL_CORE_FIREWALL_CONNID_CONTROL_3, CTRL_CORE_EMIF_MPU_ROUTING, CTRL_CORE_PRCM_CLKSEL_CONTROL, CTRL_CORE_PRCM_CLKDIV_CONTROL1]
0x1C54 CTRL_CORE_FIREWALL_CONNID_CONTROL_3 reset 0xC0CC000 — Firewall ConnID control register
  [27:24] ISS_RT_CONNID rw, [19:16] ISS_NRT1_CONNID rw, [15:12] ISS_NRT2_CONNID rw
0x1C58 CTRL_CORE_EMIF_MPU_ROUTING — EMIF MPU traffic control register
  [3] EVE1_ROUTING_ENABLE rw, [2] DSP2_ROUTING_ENABLE rw, [1] DSP1_ROUTING_ENABLE rw, [0] IPU1_ROUTING_ENABLE rw
0x1C5C CTRL_CORE_PRCM_CLKSEL_CONTROL reset 0x22222 — PRCM Clock selection control register
  [28] EVE_CLKSEL rw — EVE Clock selection control
    0=EVE1_GCLK; 1=EVE2_GCLK
  [25:24] DSP_CLKSEL rw — DSP Clock selection control
    0=DSP0_CLK (DSP2_CLK); 1=DSP1_CLK; 2=DSP2_CLK (DSP0_CLK)
  [21:20] ADC_CLKSEL rw — ADC Clock selection control
    0=SYS_CLK1; 1=SYS_CLK2; 2=XREF_CLK
  [21-4n:20-4n] RTI{n}_CLKSEL rw (n=1..5) — RTI{n} Clock selection control
    0=SYS_CLK1 (SYS_CLK1 div 4); 1=SYS_CLK2 (SYS_CLK2 div 4); 2=XREF_CLK (FUNC_32K_CLK)
0x1C60 CTRL_CORE_PRCM_CLKDIV_CONTROL1 reset 0xA0307 — PRCM Clock divider control1 register
  [31:30] RESERVED ro — Read returns 0.
  [29] DBG_STM_EXPT_CLK_HSDIV_CHANGE_ACK ro — HSDIVIDER change ack
  [28] DBG_STM_EXPT_CLK_HSDIV_EN_ACK ro — EN_ACK from HSDIVIDER
  [27] DBG_TRC_EXPT_CLK_HSDIV_CHANGE_ACK ro — HSDIVIDER change ack
  [26] DBG_TRC_EXPT_CLK_HSDIV_EN_ACK ro — EN_ACK from HSDIVIDER
  [25] DBG_ATB_CLK_HSDIV_CHANGE_ACK ro — HSDIVIDER change ack
  [24] DBG_ATB_CLK_HSDIV_EN_ACK ro — EN_ACK from HSDIVIDER
  [23] DBG_STM_EXPT_CLK_TENABLEDIV_SEL rw — 0: Control from PRCM 1: Control from Control Module - DBG_STM_EXPT_TENABLEDIV_CTRL
  [22] DBG_STM_EXPT_CLK_TENABLEDIV rw — Needs to be pulsed (LO-&gt;HI-&gt;LO) for latching the divider value in to the DPLL.
  [21:16] DBG_STM_EXPT_CLK_DIV rw — DebugSS STM Clock divider value
  [15] DBG_TRC_EXPT_CLK_TENABLEDIV_SEL rw — 0: Control from PRCM 1: Control from Control Module - DBG_TRC_EXPT_TENABLEDIV_CTRL
  [14] DBG_TRC_EXPT_CLK_TENABLEDIV rw — Needs to be pulsed (LO-&gt;HI-&gt;LO) for latching the divider value in to the DPLL.
  [13:8] DBG_TRC_EXPT_CLK_DIV rw — DebugSS TRC Clock divider value
  [6] DBG_ATB_CLK_TENABLEDIV rw — Needs to be pulsed (LO-&gt;HI-&gt;LO) for latching the divider value in to the DPLL.
  [5:0] DBG_ATB_CLK_DIV rw — DebugSS ATB Clock divider value
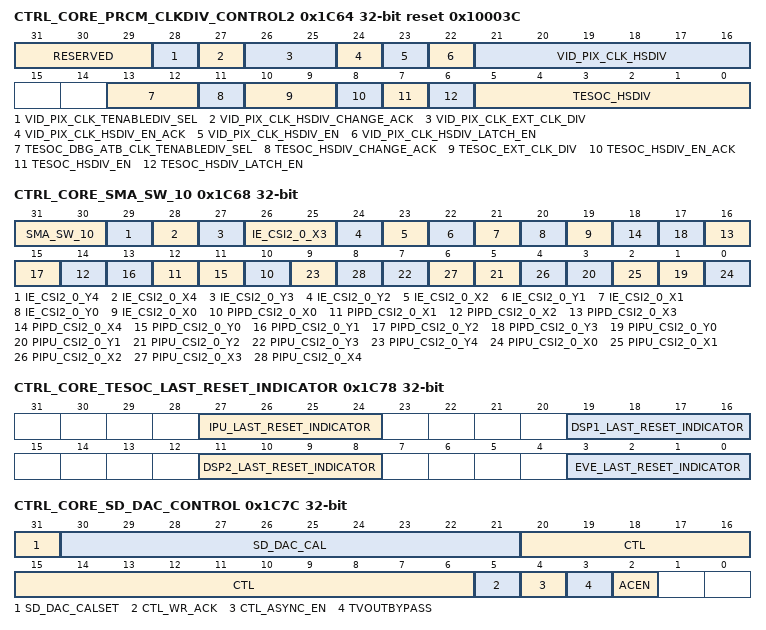
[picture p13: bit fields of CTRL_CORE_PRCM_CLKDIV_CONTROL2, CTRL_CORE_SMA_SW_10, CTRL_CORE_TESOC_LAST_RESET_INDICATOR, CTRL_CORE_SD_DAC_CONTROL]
0x1C64 CTRL_CORE_PRCM_CLKDIV_CONTROL2 reset 0x10003C — PRCM Clock divider control2 register
  [31:29] RESERVED ro — Read returns 0.
  [28] VID_PIX_CLK_TENABLEDIV_SEL rw — VID_PIX_CLK_TENABLEDIV control select: 0: Control from PRCM 1: Control from Control Module - VID_PIX_CLK_HSDIV_LATCH_EN
  [27] VID_PIX_CLK_HSDIV_CHANGE_ACK ro — HSDIVIDER change ack
  [26:25] VID_PIX_CLK_EXT_CLK_DIV rw — Video Clock divider value
    0=DIV1; 1=DIV2; 2=DIV4
  [24] VID_PIX_CLK_HSDIV_EN_ACK ro — EN_ACK from HSDIVIDER
  [23] VID_PIX_CLK_HSDIV_EN rw — Clock enable to the Video Clock HS divider
  [22] VID_PIX_CLK_HSDIV_LATCH_EN rw — Video Clock HS divider latch enable: To be toggled to latch DIV value in HSDIVIDER
  [21:16] VID_PIX_CLK_HSDIV rw — Video Clock HS divider value
  [13:12] TESOC_DBG_ATB_CLK_TENABLEDIV_SEL rw — Mux select for the TENABLE of Core DPLL HS divider 1: 0: PRCM 1: DBG_ATB_CLK 2: TESOC_EXT_CLK_HSDIV 3: Reserved
  [11] TESOC_HSDIV_CHANGE_ACK ro — HSDIVIDER change ack
  [10:9] TESOC_EXT_CLK_DIV rw — TesOC clock divider value
    0=DIV1; 1=DIV2; 2=DIV4
  [8] TESOC_HSDIV_EN_ACK ro — EN_ACK from HSDIVIDER
  [7] TESOC_HSDIV_EN rw — Clock enable to TesOC clock HS divider
  [6] TESOC_HSDIV_LATCH_EN rw — TesOC clock HS divider latch enable: To be toggled to latch DIV value in DPLL
  [5:0] TESOC_HSDIV rw — TesOC clock HS divider value
0x1C68 CTRL_CORE_SMA_SW_10 — OCP Spare Register
  [31:30] SMA_SW_10 ro — spare bits
  [29] IE_CSI2_0_Y4 rw
  [28] IE_CSI2_0_X4 rw
  [27] IE_CSI2_0_Y3 rw
  [26:25] IE_CSI2_0_X3 rw
  [24] IE_CSI2_0_Y2 rw
  [23] IE_CSI2_0_X2 rw
  [22] IE_CSI2_0_Y1 rw
  [21] IE_CSI2_0_X1 rw
  [20] IE_CSI2_0_Y0 rw
  [19] IE_CSI2_0_X0 rw
  [2n+10] PIPD_CSI2_0_X{n} rw (n=0..4)
  [2n+11] PIPD_CSI2_0_Y{n} rw (n=0..3)
  [2n+1] PIPU_CSI2_0_Y{n} rw (n=0..4)
  [2n] PIPU_CSI2_0_X{n} rw (n=0..4)
{0x1C40+4i} CTRL_CORE_SMA_SW_{i} rw (i=11..13) — OCP Spare Register
  [31:0] SMA_SW_{i}
0x1C78 CTRL_CORE_TESOC_LAST_RESET_INDICATOR — TESOC last reset indicator register
  [27:24] IPU_LAST_RESET_INDICATOR rw — IPU resert indicator. IPU writes into this bit field when it initiates self-test. IPU reads this bit field after coming up from reset after field-test and understands that the reset was due to TESOC. Software can choose to do partial boot using this indicator. For details on TESOC, refer to Tester On Chip (TESOC) in the device Safety Subsystem.
  [19:16] DSP1_LAST_RESET_INDICATOR rw — DSP1 resert indicator. DSP1 writes into this bit field when it initiates self-test. DSP1 reads this bit field after coming up from reset after field-test and understands that the reset was due to TESOC. Software can choose to do partial boot using this indicator. For details on TESOC, refer to Tester On Chip (TESOC) in the device Safety Subsystem.
  [11:8] DSP2_LAST_RESET_INDICATOR rw — DSP2 resert indicator. DSP2 writes into this bit field when it initiates self-test. DSP reads this bit field after coming up from reset after field-test and understands that the reset was due to TESOC. Software can choose to do partial boot using this indicator. For details on TESOC, refer to Tester On Chip (TESOC) in the device Safety Subsystem.
  [3:0] EVE_LAST_RESET_INDICATOR rw — EVE resert indicator. EVE writes into this bit field when it initiates self-test. EVE reads this bit field after coming up from reset after field-test and understands that the reset was due to TESOC. Software can choose to do partial boot using this indicator. For details on TESOC, refer to Tester On Chip (TESOC) in the device Safety Subsystem.
0x1C7C CTRL_CORE_SD_DAC_CONTROL access not given — SD DAC control register
  [31] SD_DAC_CALSET rw — 0x0: Data from VENC is provided to SD_DAC 0x1: Data from the SD_DAC_CAL bit field is provided to SD_DAC
  [30:21] SD_DAC_CAL rw — 10-bit data for SD_DAC test or debug purposes.
  [20:6] CTL rw — SD_DAC Control interface for reconfiguration of the module in functional mode through internal configuration registers.
  [5] CTL_WR_ACK — Used only for synchronous mode of the CTL interface. It toggles high and then low when an asynchronous write on the CTL bus has been acknowledged by the SD_DAC module. (access RW W1toClr)
  [4] CTL_ASYNC_EN rw — Asynchronous mode enable for CTL interface. 0x0: Synchronous mode 0x1: Asynchronous mode
  [3] TVOUTBYPASS rw — TVOUT Bypass enable. 0x0: Normal mode. Video Buffer is not bypassed 0x1: Bypass mode. Video Buffer is bypassed
  [2] ACEN rw — AC coupling enable. 0x0: DC coupling selected 0x1: AC coupling selected
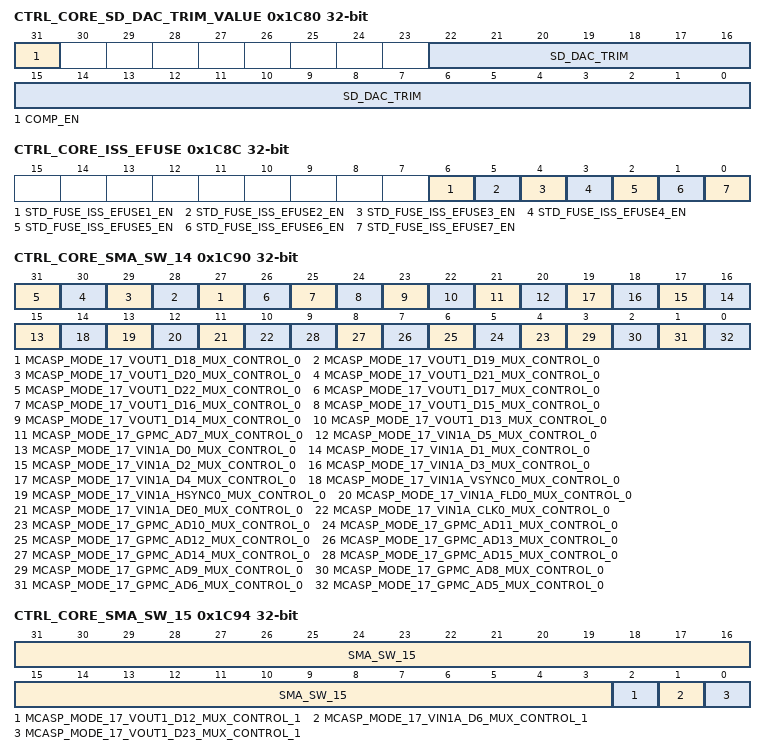
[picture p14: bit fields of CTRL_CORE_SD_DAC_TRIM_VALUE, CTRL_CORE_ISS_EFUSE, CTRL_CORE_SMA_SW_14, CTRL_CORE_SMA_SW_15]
0x1C80 CTRL_CORE_SD_DAC_TRIM_VALUE — SD DAC trim value
  [31] COMP_EN rw — Optional control for lower output swing. 0x0: High full-scale output swing 0x1: Low full-scale output swing
  [22:0] SD_DAC_TRIM rw — SD DAC trim value
0x1C84 CTRL_CORE_ADC_ERROR_OFFSET — ADC Error offset register
  [7:0] ERROR_OFFSET rw — Error offset value driven from efuse with optional override
0x1C88 CTRL_CORE_IPU_WAKEUP reset 0x1 — IPU wakeup enable
  [0] IPU_WKUP_EN rw
0x1C8C CTRL_CORE_ISS_EFUSE — ADC Error offset register
  [7-n] STD_FUSE_ISS_EFUSE{n}_EN rw (n=1..7) — Error offset value driven from efuse with optional override
0x1C90 CTRL_CORE_SMA_SW_14 rw — OCP Spare Register (SR1.0 Only). For SR2.0 devices this register controls MCASP2 and MCASP3 signal muxing.
  [n+9] MCASP_MODE_17_VOUT1_D{n}_MUX_CONTROL_0 (n=18..22) — SR2.0 Only:0x0: Function 17 for pad vout1_d{n} not selected0x1: mcasp2_axr{n-18} selected on pad vout1_d{n} as function 17
  [26] MCASP_MODE_17_VOUT1_D17_MUX_CONTROL_0 — SR2.0 Only:0x0: Function 17 for pad vout1_d17 not selected0x1: mcasp2_fsr selected on pad vout1_d17 as function 17
  [25] MCASP_MODE_17_VOUT1_D16_MUX_CONTROL_0 — SR2.0 Only:0x0: Function 17 for pad vout1_d16 not selected0x1: This option is not supported and must not be used.
  [24] MCASP_MODE_17_VOUT1_D15_MUX_CONTROL_0 — SR2.0 Only:0x0: Function 17 for pad vout1_d15 not selected0x1: mcasp2_fsx selected on pad vout1_d15 as function 17
  [23] MCASP_MODE_17_VOUT1_D14_MUX_CONTROL_0 — SR2.0 Only:0x0: Function 17 for pad vout1_d14 not selected0x1: mcasp2_aclkx selected on pad vout1_d14 as function 17
  [22] MCASP_MODE_17_VOUT1_D13_MUX_CONTROL_0 — SR2.0 Only:0x0: Function 17 for pad vout1_d13 not selected0x1: mcasp2_aclkr selected on pad vout1_d13 as function 17
  [21] MCASP_MODE_17_GPMC_AD7_MUX_CONTROL_0 — SR2.0 Only:0x0: Function 17 for pad gpmc_ad7 not selected0x1: mcasp2_ahclkx selected on pad gpmc_ad7 as function 17
  [20] MCASP_MODE_17_VIN1A_D5_MUX_CONTROL_0 — SR2.0 Only:0x0: Function 17 for pad vin1a_d5 not selected0x1: mcasp3_ahclkx selected on pad vin1a_d5 as function 17
  [n+15] MCASP_MODE_17_VIN1A_D{n}_MUX_CONTROL_0 (n=0..4) — SR2.0 Only:0x0: Function 17 for pad vin1a_d{n} not selected0x1: mcasp3_axr{n+1} selected on pad vin1a_d{n} as function 17
  [14] MCASP_MODE_17_VIN1A_VSYNC0_MUX_CONTROL_0 — SR2.0 Only:0x0: Function 17 for pad vin1a_vsync0 not selected0x1: mcasp3_axr0 selected on pad vin1a_vsync0 as function 17
  [13] MCASP_MODE_17_VIN1A_HSYNC0_MUX_CONTROL_0 — SR2.0 Only:0x0: Function 17 for pad vin1a_hsync0 not selected0x1: mcasp3_fsr selected on pad vin1a_hsync0 as function 17
  [12] MCASP_MODE_17_VIN1A_FLD0_MUX_CONTROL_0 — SR2.0 Only:0x0: Function 17 for pad vin1a_fld0 not selected0x1: mcasp3_aclkr selected on pad vin1a_fld0 as function 17
  [11] MCASP_MODE_17_VIN1A_DE0_MUX_CONTROL_0 — SR2.0 Only:0x0: Function 17 for pad vin1a_de0 not selected0x1: This option is not supported and must not be used.
  [10] MCASP_MODE_17_VIN1A_CLK0_MUX_CONTROL_0 — SR2.0 Only:0x0: Function 17 for pad vin1a_clk0 not selected0x1: mcasp3_aclkx selected on pad vin1a_clk0 as function 17
  [n-6] MCASP_MODE_17_GPMC_AD{n}_MUX_CONTROL_0 (n=10..15) — SR2.0 Only:0x0: Function 17 for pad gpmc_ad{n} not selected0x1: mcasp2_axr{n-10} selected on pad gpmc_ad{n} as function 17
  [3] MCASP_MODE_17_GPMC_AD9_MUX_CONTROL_0 — SR2.0 Only:0x0: Function 17 for pad gpmc_ad9 not selected0x1: mcasp2_fsr selected on pad gpmc_ad9 as function 17
  [2] MCASP_MODE_17_GPMC_AD8_MUX_CONTROL_0 — SR2.0 Only:0x0: Function 17 for pad gpmc_ad8 not selected0x1: mcasp2_aclkr selected on pad gpmc_ad8 as function 17
  [1] MCASP_MODE_17_GPMC_AD6_MUX_CONTROL_0 — SR2.0 Only:0x0: Function 17 for pad gpmc_ad6 not selected0x1: mcasp2_fsx selected on pad gpmc_ad6 as function 17
  [0] MCASP_MODE_17_GPMC_AD5_MUX_CONTROL_0 — SR2.0 Only:0x0: Function 17 for pad gpmc_ad5 not selected0x1: mcasp2_aclkx selected on pad gpmc_ad5 as function 17
0x1C94 CTRL_CORE_SMA_SW_15 rw — OCP Spare Register (SR1.0 Only). For SR2.0 devices some bits of this register control MCASP2 and MCASP3 signal muxing.
  [31:3] SMA_SW_15 — OCP Spare Bits
  [2] MCASP_MODE_17_VOUT1_D12_MUX_CONTROL_1 — SR2.0 Only:0x0: Function 17 for pad vout1_d12 not selected0x1: mcasp2_ahclkx selected on pad vout1_d12 as function 17
  [1] MCASP_MODE_17_VIN1A_D6_MUX_CONTROL_1 — SR2.0 Only:0x0: Function 17 for pad vin1a_d6 not selected0x1: mcasp3_fsx selected on pad vin1a_d6 as function 17
  [0] MCASP_MODE_17_VOUT1_D23_MUX_CONTROL_1 — SR2.0 Only:0x0: Function 17 for pad vout1_d23 not selected0x1: mcasp2_axr5 selected on pad vout1_d23 as function 17
0x1C98 CTRL_CORE_SMA_SW_16 rw — OCP Spare Register (SR1.0 Only). For SR2.0 bit 0 is functional.
  [31:1] SMA_SW_16 — OCP Spare Register
  [0] CORE_DPLL_INPUT_CLK_SELECTION — SR2.0 Only:DPLL_CORE input clock selection.0x0: SYS_CLK1 selected as input clock (REF_CLK) for DPLL_CORE0x1: SYS_CLK2 selected as input clock (REF_CLK) for DPLL_CORE
0x1C9C CTRL_CORE_SMA_SW_17 reset 0x800 (reset mask 0xFFFFFFC0) — OCP Spare Register (SR1.0 Only). For SR2.0 this register holds some controls and status bits for H14 HS divider of DPLL_GMAC_DSP which is the source of MCAN functional clock (MCAN_CLK).
  [31:12] SMA_SW_17 rw — OCP Spare Bits
  [11] MCAN_CLK_HSDIV_CHANGE_ACK ro — SR2.0 Only:Acknowledge flag which indicates that the on-the-fly change of H14 divider of DPLL_GMAC_DSP is done. This bit changes its state (0 to 1 or 1 to 0) on each on-the-fly change of H14.
  [10] MCAN_CLK_HSDIV_EN_ACK ro — SR2.0 Only:Indicates whether CLKOUTX2_H14 of DPLL_GMAC_DSP is enabled or not.0x0: CLKOUTX2_H14 is disabled0x1: CLKOUTX2_H14 is enabled
  [9] MCAN_CLK_TENABLEDIV_SEL rw — SR2.0 Only:TENABLEDIV control select for H14 of DPLL_GMAC_DSP0x0: Control from PRCM0x1: Control from Control Module (bit
  [7] MCAN_CLK_HSDIV_EN rw — SR2.0 Only:Output clock (CLKOUTX2_H14) enable for H14 of DPLL_GMAC_DSP0x0: Output clock disabled0x1: Output clock enabled
  [6] MCAN_CLK_HSDIV_LATCH_EN rw — SR2.0 Only:To be toggled (LO-&gt;HI-&gt;LO) to latch MCAN_CLK_HSDIV value in H14 of DPLL_GMAC_DSP. This bit takes effect only when bit
  [5:0] MCAN_CLK_HSDIV rw — SR2.0 Only:Divider value for H14 of DPLL_GMAC_DSP
0x1CA0 CTRL_CORE_ROM_CPU0_BRANCH rw
  [31:0] ROM_CPU0_BRANCH
0x1CA4 CTRL_CORE_ROM_CPU1_BRANCH rw
  [31:0] ROM_CPU1_BRANCH
0x1CA8 CTRL_CORE_ROM_AUXBOOT0 rw
  [31:0] ROM_AUXBOOT0
0x1CAC CTRL_CORE_ROM_AUXBOOT1 rw
  [31:0] ROM_AUXBOOT1
{0x1C68+4i} CTRL_CORE_SMA_SW_{i} ro (i=18..21) — OCP Spare Register
  [31:0] SMA_SW_{i}
0x1CC0 CTRL_CORE_SMA_SW_22 rw — OCP Spare Register (SR1.0 Only). For SR2.0 bits [17:0] are used.
  [31:18] SMA_SW_22 — OCP Spare Register
  [17:0] CORE_DPLL_REGMF_CONTROL — SR2.0 Only:Fractional part of the software-configured multiplication ratio M of DPLL_CORE. To disable the fractional part this bit field must be set to 0x0.
{0x1C68+4i} CTRL_CORE_SMA_SW_{i} rw (i=23..27) — OCP Spare Register
  [31:0] SMA_SW_{i}
